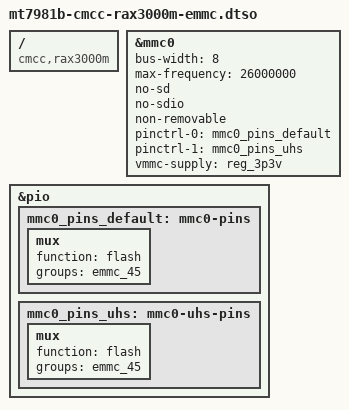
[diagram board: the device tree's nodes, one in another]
// SPDX-License-Identifier: GPL-2.0-or-later OR MIT

/dts-v1/;
/plugin/;

/ {
	compatible = "cmcc,rax3000m", "mediatek,mt7981";

	fragment@0 {
		target = <&mmc0>;
		__overlay__ {
			bus-width = <8>;
			max-frequency = <26000000>;
			no-sd;
			no-sdio;
			non-removable;
			pinctrl-names = "default", "state_uhs";
			pinctrl-0 = <&mmc0_pins_default>;
			pinctrl-1 = <&mmc0_pins_uhs>;
			vmmc-supply = <&reg_3p3v>;
			status = "okay";
		};
	};

	fragment@1 {
		target = <&pio>;
		__overlay__ {
			mmc0_pins_default: mmc0-pins {
				mux {
					function = "flash";
					groups = "emmc_45";
				};
			};

			mmc0_pins_uhs: mmc0-uhs-pins {
				mux {
					function = "flash";
					groups = "emmc_45";
				};
			};
		};
	};
};
